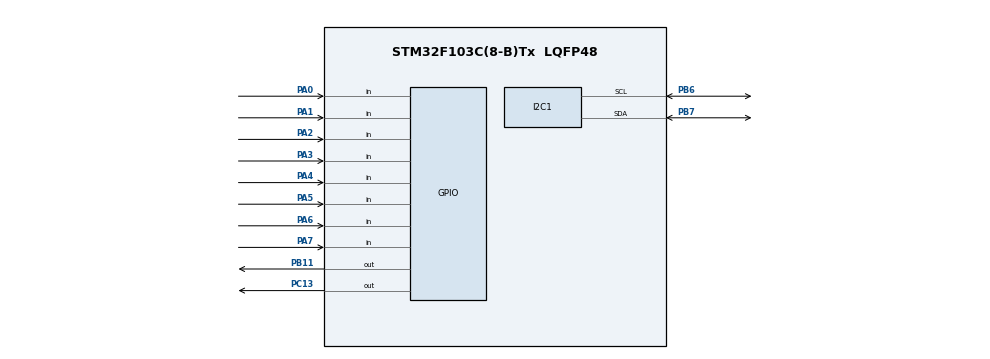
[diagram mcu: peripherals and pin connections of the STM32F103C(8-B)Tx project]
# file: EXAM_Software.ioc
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I2C1.I2C_Mode=I2C_Fast
Mcu.Family=STM32F1
Mcu.Name=STM32F103C(8-B)Tx
Mcu.Package=LQFP48
NVIC.PriorityGroup=NVIC_PRIORITYGROUP_4
PA0-WKUP.GPIO_PuPd=GPIO_PULLUP
PA0-WKUP.Signal=GPIO_Input
PA1.GPIO_PuPd=GPIO_PULLUP
PA1.Signal=GPIO_Input
PA13.Mode=Serial_Wire
PA13.Signal=SYS_JTMS-SWDIO
PA14.Mode=Serial_Wire
PA14.Signal=SYS_JTCK-SWCLK
PA2.GPIO_PuPd=GPIO_PULLUP
PA2.Signal=GPIO_Input
PA3.GPIO_PuPd=GPIO_PULLUP
PA3.Signal=GPIO_Input
PA4.GPIO_PuPd=GPIO_PULLUP
PA4.Signal=GPIO_Input
PA5.GPIO_PuPd=GPIO_PULLUP
PA5.Signal=GPIO_Input
PA6.GPIO_PuPd=GPIO_PULLUP
PA6.Signal=GPIO_Input
PA7.GPIO_PuPd=GPIO_PULLUP
PA7.Signal=GPIO_Input
PB11.PinState=GPIO_PIN_RESET
PB11.Signal=GPIO_Output
PB6.Mode=I2C
PB6.Signal=I2C1_SCL
PB7.Mode=I2C
PB7.Signal=I2C1_SDA
PC13-TAMPER-RTC.PinState=GPIO_PIN_SET
PC13-TAMPER-RTC.Signal=GPIO_Output
ProjectManager.HeapSize=0x200
ProjectManager.StackSize=0x400
ProjectManager.TargetToolchain=CMake
RCC.APB1Freq_Value=8000000
RCC.APB2Freq_Value=8000000
board=custom

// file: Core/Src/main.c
/* USER CODE BEGIN Header */
/**
# ******************************************************************************
 * @file           : main.c
 * @brief          : Main program body
 ******************************************************************************
 * @attention
 *
 * Copyright (c) 2026 STMicroelectronics.
 * All rights reserved.
 *
 * This software is licensed under terms that can be found in the LICENSE file
 * in the root directory of this software component.
 * If no LICENSE file comes with this software, it is provided AS-IS.
 *
 ******************************************************************************
 */
/* USER CODE END Header */
#include "main.h"

/* USER CODE BEGIN Includes */
#include "application.hpp"
/* USER CODE END Includes */

I2C_HandleTypeDef hi2c1;

void SystemClock_Config(void);
static void MX_GPIO_Init(void);
static void MX_I2C1_Init(void);

int main(void)
{

  /* MCU Configuration--------------------------------------------------------*/

  /* Reset of all peripherals, Initializes the Flash interface and the Systick. */
  HAL_Init();

  /* Configure the system clock */
  SystemClock_Config();

  /* Initialize all configured peripherals */
  MX_GPIO_Init();
  MX_I2C1_Init();
  /* USER CODE BEGIN 2 */
  start();
  /* USER CODE END 2 */

  /* Infinite loop */
  /* USER CODE BEGIN WHILE */
  while (1)
  {
    update();
    /* USER CODE END WHILE */

  }
}

void SystemClock_Config(void)
{
  RCC_OscInitTypeDef RCC_OscInitStruct = {0};
  RCC_ClkInitTypeDef RCC_ClkInitStruct = {0};

  /** Initializes the RCC Oscillators according to the specified parameters
   * in the RCC_OscInitTypeDef structure.
   */
  RCC_OscInitStruct.OscillatorType = RCC_OSCILLATORTYPE_HSI;
  RCC_OscInitStruct.HSIState = RCC_HSI_ON;
  RCC_OscInitStruct.HSICalibrationValue = RCC_HSICALIBRATION_DEFAULT;
  RCC_OscInitStruct.PLL.PLLState = RCC_PLL_NONE;
  if (HAL_RCC_OscConfig(&RCC_OscInitStruct) != HAL_OK)
  {
    Error_Handler();
  }

  /** Initializes the CPU, AHB and APB buses clocks
   */
  RCC_ClkInitStruct.ClockType = RCC_CLOCKTYPE_HCLK | RCC_CLOCKTYPE_SYSCLK | RCC_CLOCKTYPE_PCLK1 | RCC_CLOCKTYPE_PCLK2;
  RCC_ClkInitStruct.SYSCLKSource = RCC_SYSCLKSOURCE_HSI;
  RCC_ClkInitStruct.AHBCLKDivider = RCC_SYSCLK_DIV1;
  RCC_ClkInitStruct.APB1CLKDivider = RCC_HCLK_DIV1;
  RCC_ClkInitStruct.APB2CLKDivider = RCC_HCLK_DIV1;

  if (HAL_RCC_ClockConfig(&RCC_ClkInitStruct, FLASH_LATENCY_0) != HAL_OK)
  {
    Error_Handler();
  }
}

static void MX_I2C1_Init(void)
{

  hi2c1.Instance = I2C1;
  hi2c1.Init.ClockSpeed = 400000;
  hi2c1.Init.DutyCycle = I2C_DUTYCYCLE_2;
  hi2c1.Init.OwnAddress1 = 0;
  hi2c1.Init.AddressingMode = I2C_ADDRESSINGMODE_7BIT;
  hi2c1.Init.DualAddressMode = I2C_DUALADDRESS_DISABLE;
  hi2c1.Init.OwnAddress2 = 0;
  hi2c1.Init.GeneralCallMode = I2C_GENERALCALL_DISABLE;
  hi2c1.Init.NoStretchMode = I2C_NOSTRETCH_DISABLE;
  if (HAL_I2C_Init(&hi2c1) != HAL_OK)
  {
    Error_Handler();
  }
}

static void MX_GPIO_Init(void)
{
  GPIO_InitTypeDef GPIO_InitStruct = {0};

  /* GPIO Ports Clock Enable */
  __HAL_RCC_GPIOC_CLK_ENABLE();
  __HAL_RCC_GPIOA_CLK_ENABLE();
  __HAL_RCC_GPIOB_CLK_ENABLE();

  /*Configure GPIO pin Output Level */
  HAL_GPIO_WritePin(GPIOC, GPIO_PIN_13, GPIO_PIN_SET);

  /*Configure GPIO pin Output Level */
  HAL_GPIO_WritePin(GPIOB, GPIO_PIN_11, GPIO_PIN_RESET);

  /*Configure GPIO pin : PC13 */
  GPIO_InitStruct.Pin = GPIO_PIN_13;
  GPIO_InitStruct.Mode = GPIO_MODE_OUTPUT_PP;
  GPIO_InitStruct.Pull = GPIO_NOPULL;
  GPIO_InitStruct.Speed = GPIO_SPEED_FREQ_LOW;
  HAL_GPIO_Init(GPIOC, &GPIO_InitStruct);

  /*Configure GPIO pins : PA0 PA1 PA2 PA3
                           PA4 PA5 PA6 PA7 */
  GPIO_InitStruct.Pin = GPIO_PIN_0 | GPIO_PIN_1 | GPIO_PIN_2 | GPIO_PIN_3 | GPIO_PIN_4 | GPIO_PIN_5 | GPIO_PIN_6 | GPIO_PIN_7;
  GPIO_InitStruct.Mode = GPIO_MODE_INPUT;
  GPIO_InitStruct.Pull = GPIO_PULLUP;
  HAL_GPIO_Init(GPIOA, &GPIO_InitStruct);

  /*Configure GPIO pin : PB11 */
  GPIO_InitStruct.Pin = GPIO_PIN_11;
  GPIO_InitStruct.Mode = GPIO_MODE_OUTPUT_PP;
  GPIO_InitStruct.Pull = GPIO_NOPULL;
  GPIO_InitStruct.Speed = GPIO_SPEED_FREQ_LOW;
  HAL_GPIO_Init(GPIOB, &GPIO_InitStruct);

}

void Error_Handler(void)
{
  __disable_irq();
  while (1)
  {
  }
}
#ifdef USE_FULL_ASSERT
/**
 * @brief  Reports the name of the source file and the source line number
 *         where the assert_param error has occurred.
 * @param  file: pointer to the source file name
 * @param  line: assert_param error line source number
 * @retval None
 */
void assert_failed(uint8_t *file, uint32_t line)
{
  /* USER CODE BEGIN 6 */
  /* User can add his own implementation to report the file name and line
     number, ex: printf("Wrong parameters value: file %s on line %d\r\n", file,
     line) */
  /* USER CODE END 6 */
}
#endif /* USE_FULL_ASSERT */
